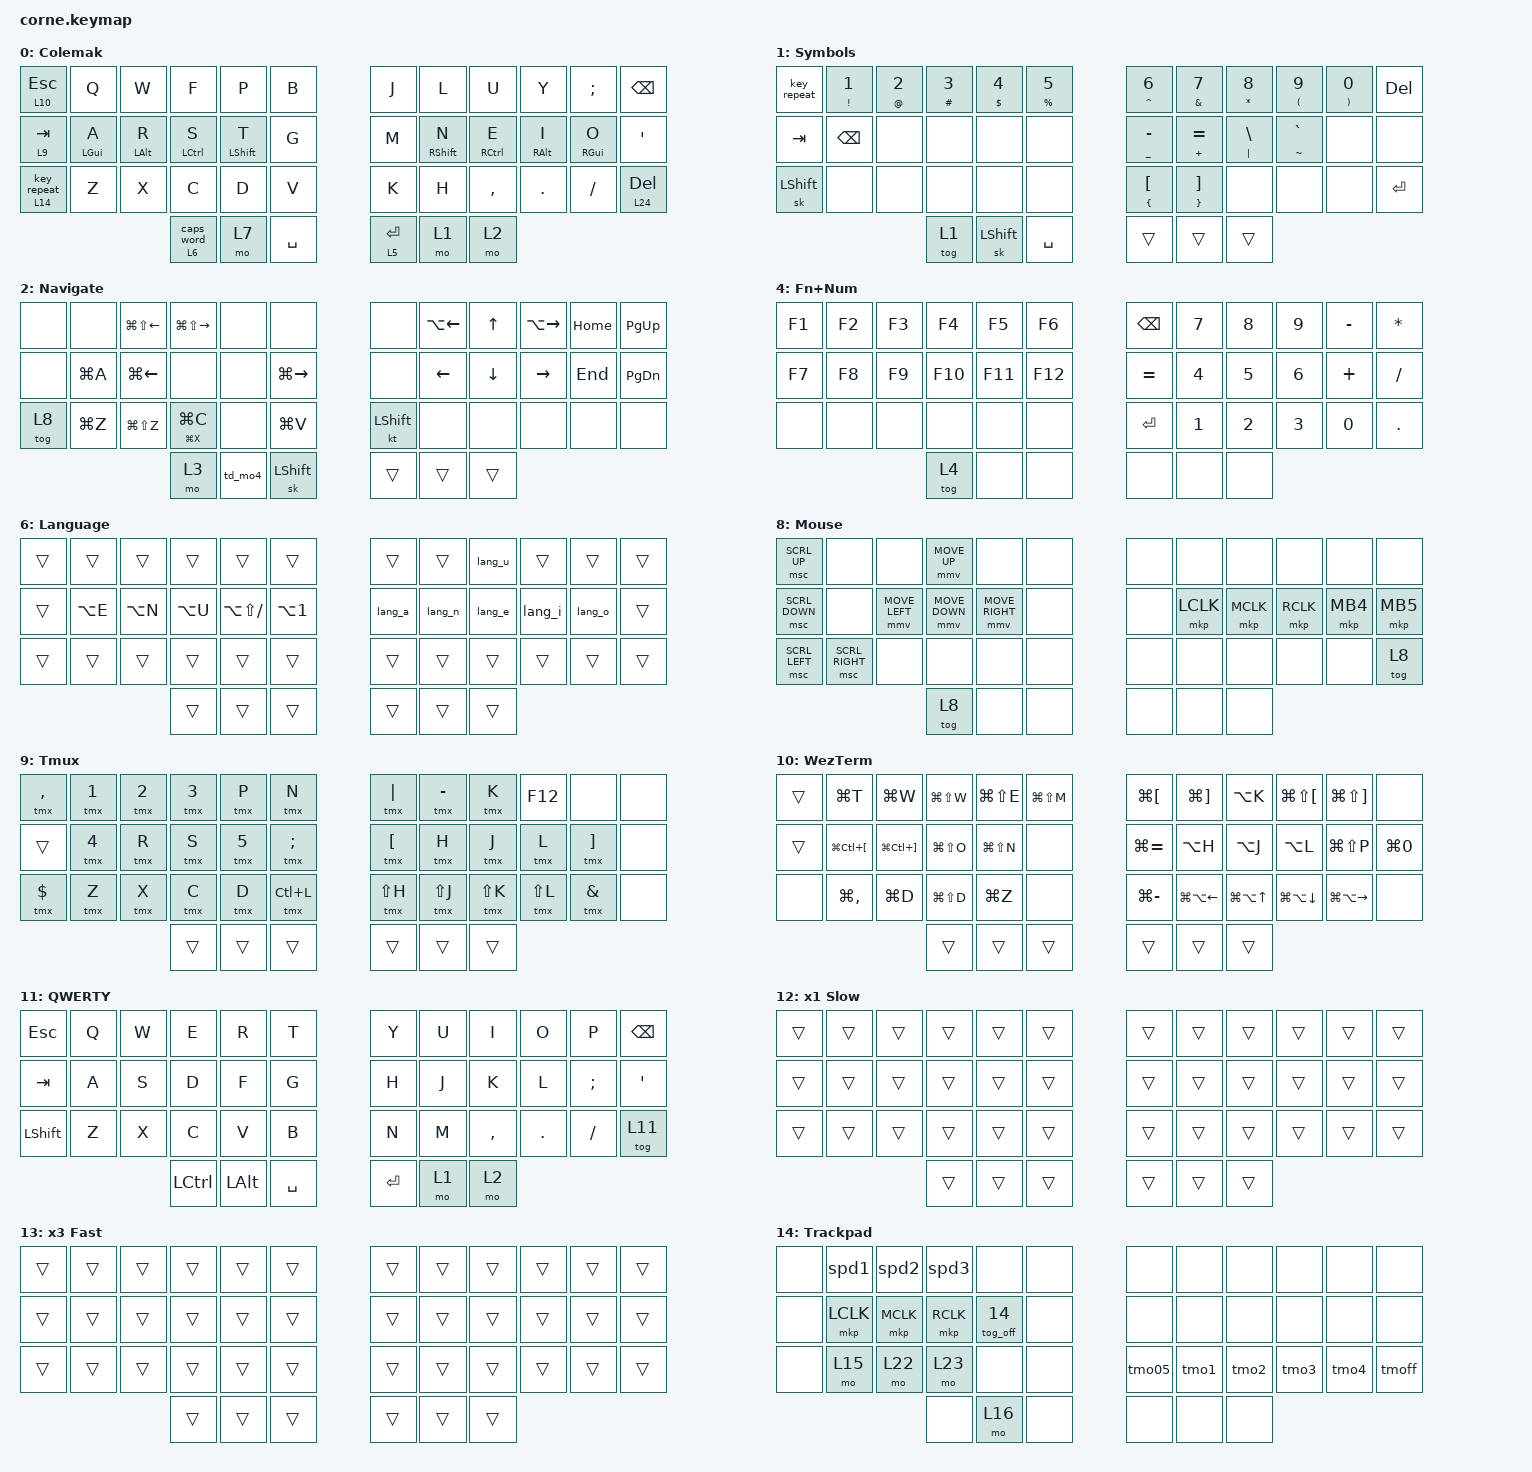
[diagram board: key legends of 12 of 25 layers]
/*
 * Copyright (c) 2020 The ZMK Contributors
 *
 * SPDX-License-Identifier: MIT
 */

#include <behaviors.dtsi>
#include <dt-bindings/zmk/keys.h>
#include <dt-bindings/zmk/bt.h>
#include <dt-bindings/led/led.h>
#include <dt-bindings/zmk/outputs.h>
#include <dt-bindings/zmk/rgb.h>
#include <dt-bindings/zmk/backlight.h>
#define ZMK_POINTING_DEFAULT_MOVE_VAL 2000  // default: 600
/* 320 = 20 * 16: con CONFIG_ZMK_POINTING_SMOOTH_SCROLLING el host divide
 * cada unidad de rueda por el resolution multiplier (16), así que el valor
 * se multiplica para mantener la velocidad efectiva de siempre (20). */
#define ZMK_POINTING_DEFAULT_SCRL_VAL 320   // default: 10
#include <dt-bindings/zmk/pointing.h>

/* nice!view — CS soldado al pin 010 (P0.10), no al default del adapter (P0.06).
 * pro_micro 16 = P0.10 en nice!nano v2.
 * idx 1 = CS del Cirque (P0.09, activo bajo): el keymap es la última palabra
 * del devicetree y pisaría el array del shield cirque_right, así que las dos
 * entradas viven aquí. En la izquierda la segunda es inofensiva (sin reg 1). */
&nice_view_spi {
    cs-gpios = <&pro_micro 16 GPIO_ACTIVE_HIGH>, <&gpio0 9 GPIO_ACTIVE_LOW>;
};

/* P0.09/P0.10 son pines NFC del nRF52840: liberarlos como GPIO para usar
 * P0.10 como CS del nice!view y P0.09 como CS del Cirque. Escribe UICR al
 * primer boot; solo se revierte borrando UICR. */
&uicr {
    nfct-pins-as-gpios;
};

/ {
    /* ------------------------------------------------------------------ */
    /* Combos                                                               */
    /*   J+L (pos 6+7) → ESC  — accesible sin mover manos del home row    */
    /* ------------------------------------------------------------------ */
    combos {
        compatible = "zmk,combos";
        combo_esc {
            timeout-ms = <50>;
            key-positions = <6 7>;
            bindings = <&kp ESC>;
            /* No en QWERTY (L11): ahí pos 6+7 = Y+U y tipear "yu" dispararía ESC */
            /* Todas las capas menos QWERTY (11). Incluye las fantasma
             * 12-16: los combos filtran por la capa MÁS ALTA activa
             * (combo.c usa zmk_keymap_highest_layer_active), así que sin
             * ellas el combo ESC moría con x1/x3 seleccionado o durante la
             * ventana auto-Trackpad. */
            layers = <0 1 2 3 4 5 6 7 8 9 10 12 13 14 15 16 17 18 19 20 21 22 23 24>;
        };
        combo_sys {
            timeout-ms = <50>;
            key-positions = <38 41>;
            bindings = <&mo 3>;
        };
    };

    behaviors {
        /* Home Row Mods — izquierda: hold solo al presionar mano derecha --- */
        hml: homerow_mods_left {
            compatible = "zmk,behavior-hold-tap";
            #binding-cells = <2>;
            tapping-term-ms = <280>;
            quick-tap-ms = <175>;
            require-prior-idle-ms = <200>;
            flavor = "balanced";
            hold-trigger-key-positions = <6 7 8 9 10 11 18 19 20 21 22 23 30 31 32 33 34 35 39 40 41>;
            hold-trigger-on-release;
            bindings = <&kp>, <&kp>;
        };

        /* Left outer thumb: tap→CapsWord / hold→Lang (L6) -------------------- */
        lang_cw: lang_caps_word {
            compatible = "zmk,behavior-hold-tap";
            #binding-cells = <2>;
            tapping-term-ms = <200>;
            quick-tap-ms = <0>;
            flavor = "tap-preferred";
            bindings = <&mo>, <&caps_word>;
        };

        /* REPT-pos (meñique izq inferior): tap→key_repeat / hold→Trackpad (L14) */
        tp_rept: trackpad_or_repeat {
            compatible = "zmk,behavior-hold-tap";
            #binding-cells = <2>;
            tapping-term-ms = <200>;
            quick-tap-ms = <0>;
            flavor = "tap-preferred";
            bindings = <&mo>, <&key_repeat>;
        };

        /* DEL-pos (meñique der inferior): tap→DEL / hold→Nvim (L24) — espejo
         * del tp_rept izquierdo. */
        nv_del: nvim_or_del {
            compatible = "zmk,behavior-hold-tap";
            #binding-cells = <2>;
            tapping-term-ms = <200>;
            quick-tap-ms = <0>;
            flavor = "tap-preferred";
            bindings = <&mo>, <&kp>;
        };

        /* Toggles explícitos para el selector de velocidad del trackpad ---- */
        tog_on: toggle_layer_on {
            compatible = "zmk,behavior-toggle-layer";
            #binding-cells = <1>;
            toggle-mode = "on";
        };
        tog_off: toggle_layer_off {
            compatible = "zmk,behavior-toggle-layer";
            #binding-cells = <1>;
            toggle-mode = "off";
        };
        /* Selector radio-button x1/x2/x3: capas fantasma 12 (slow) y 13 (fast),
         * transparentes al tipeo; solo conmutan el escalador del trackpad
         * (overrides por capa en cirque_left.overlay). x2 = ninguna activa. */
        spd1: speed_slow_select {
            compatible = "zmk,behavior-macro";
            #binding-cells = <0>;
            bindings = <&tog_off 13>, <&tog_on 12>;
        };
        spd2: speed_normal_select {
            compatible = "zmk,behavior-macro";
            #binding-cells = <0>;
            bindings = <&tog_off 12>, <&tog_off 13>;
        };
        spd3: speed_fast_select {
            compatible = "zmk,behavior-macro";
            #binding-cells = <0>;
            bindings = <&tog_off 12>, <&tog_on 13>;
        };

        /* Selector radio-button del timeout del auto-layer Trackpad: capas
         * fantasma 17-21 (overrides en cirque_left.overlay). 2s = default,
         * ninguna activa. Mientras una esté activa la pantalla muestra su
         * nombre como capa superior (mismo tradeoff que x1/x3). */
        tmo05: tmo_half_select {
            compatible = "zmk,behavior-macro";
            #binding-cells = <0>;
            bindings = <&tog_off 18>, <&tog_off 19>, <&tog_off 20>, <&tog_off 21>, <&tog_on 17>;
        };
        tmo1: tmo_1s_select {
            compatible = "zmk,behavior-macro";
            #binding-cells = <0>;
            bindings = <&tog_off 17>, <&tog_off 19>, <&tog_off 20>, <&tog_off 21>, <&tog_on 18>;
        };
        tmo2: tmo_2s_default_select {
            compatible = "zmk,behavior-macro";
            #binding-cells = <0>;
            bindings = <&tog_off 17>, <&tog_off 18>, <&tog_off 19>, <&tog_off 20>, <&tog_off 21>;
        };
        tmo3: tmo_3s_select {
            compatible = "zmk,behavior-macro";
            #binding-cells = <0>;
            bindings = <&tog_off 17>, <&tog_off 18>, <&tog_off 20>, <&tog_off 21>, <&tog_on 19>;
        };
        tmo4: tmo_4s_select {
            compatible = "zmk,behavior-macro";
            #binding-cells = <0>;
            bindings = <&tog_off 17>, <&tog_off 18>, <&tog_off 19>, <&tog_off 21>, <&tog_on 20>;
        };
        tmoff: tmo_no_auto_select {
            compatible = "zmk,behavior-macro";
            #binding-cells = <0>;
            bindings = <&tog_off 17>, <&tog_off 18>, <&tog_off 19>, <&tog_off 20>, <&tog_on 21>;
        };

        /* Macros capa Nvim (L24): cada una tipea la secuencia <leader>…
         * (leader = SPACE). Solo tienen sentido en modo normal de nvim;
         * en insert tipearían la secuencia literal. FMT envía F mayúscula
         * (<leader>F): la f minúscula es prefijo del grupo find en nvim
         * y dispararía con lag de timeoutlen. */
        nv_sm:  nv_smart_find  { compatible = "zmk,behavior-macro"; #binding-cells = <0>; bindings = <&kp SPACE>, <&kp SPACE>; };
        nv_ff:  nv_find_files  { compatible = "zmk,behavior-macro"; #binding-cells = <0>; bindings = <&kp SPACE>, <&kp F>, <&kp F>; };
        nv_fg:  nv_live_grep   { compatible = "zmk,behavior-macro"; #binding-cells = <0>; bindings = <&kp SPACE>, <&kp F>, <&kp G>; };
        nv_sw:  nv_grep_word   { compatible = "zmk,behavior-macro"; #binding-cells = <0>; bindings = <&kp SPACE>, <&kp S>, <&kp W>; };
        nv_bu:  nv_buffers     { compatible = "zmk,behavior-macro"; #binding-cells = <0>; bindings = <&kp SPACE>, <&kp COMMA>; };
        nv_fr:  nv_recent      { compatible = "zmk,behavior-macro"; #binding-cells = <0>; bindings = <&kp SPACE>, <&kp F>, <&kp R>; };
        nv_h1:  nv_harpoon_1   { compatible = "zmk,behavior-macro"; #binding-cells = <0>; bindings = <&kp SPACE>, <&kp N1>; };
        nv_h2:  nv_harpoon_2   { compatible = "zmk,behavior-macro"; #binding-cells = <0>; bindings = <&kp SPACE>, <&kp N2>; };
        nv_h3:  nv_harpoon_3   { compatible = "zmk,behavior-macro"; #binding-cells = <0>; bindings = <&kp SPACE>, <&kp N3>; };
        nv_h4:  nv_harpoon_4   { compatible = "zmk,behavior-macro"; #binding-cells = <0>; bindings = <&kp SPACE>, <&kp N4>; };
        nv_ha:  nv_harpoon_add { compatible = "zmk,behavior-macro"; #binding-cells = <0>; bindings = <&kp SPACE>, <&kp H>, <&kp A>; };
        nv_ex:  nv_explorer    { compatible = "zmk,behavior-macro"; #binding-cells = <0>; bindings = <&kp SPACE>, <&kp E>; };
        nv_w:   nv_save        { compatible = "zmk,behavior-macro"; #binding-cells = <0>; bindings = <&kp SPACE>, <&kp W>; };
        nv_q:   nv_quit        { compatible = "zmk,behavior-macro"; #binding-cells = <0>; bindings = <&kp SPACE>, <&kp Q>; };
        nv_nh:  nv_nohl        { compatible = "zmk,behavior-macro"; #binding-cells = <0>; bindings = <&kp SPACE>, <&kp H>; };
        nv_gg:  nv_lazygit     { compatible = "zmk,behavior-macro"; #binding-cells = <0>; bindings = <&kp SPACE>, <&kp G>, <&kp G>; };
        nv_gs:  nv_git_status  { compatible = "zmk,behavior-macro"; #binding-cells = <0>; bindings = <&kp SPACE>, <&kp G>, <&kp S>; };
        nv_gd:  nv_git_diff    { compatible = "zmk,behavior-macro"; #binding-cells = <0>; bindings = <&kp SPACE>, <&kp G>, <&kp D>; };
        nv_gb:  nv_git_branch  { compatible = "zmk,behavior-macro"; #binding-cells = <0>; bindings = <&kp SPACE>, <&kp G>, <&kp B>; };
        nv_ca:  nv_code_action { compatible = "zmk,behavior-macro"; #binding-cells = <0>; bindings = <&kp SPACE>, <&kp C>, <&kp A>; };
        nv_rn:  nv_rename      { compatible = "zmk,behavior-macro"; #binding-cells = <0>; bindings = <&kp SPACE>, <&kp R>, <&kp N>; };
        nv_fmt: nv_format      { compatible = "zmk,behavior-macro"; #binding-cells = <0>; bindings = <&kp SPACE>, <&kp LS(F)>; };
        nv_ss:  nv_symbols     { compatible = "zmk,behavior-macro"; #binding-cells = <0>; bindings = <&kp SPACE>, <&kp S>, <&kp S>; };
        nv_xx:  nv_trouble     { compatible = "zmk,behavior-macro"; #binding-cells = <0>; bindings = <&kp SPACE>, <&kp X>, <&kp X>; };
        nv_cc:  nv_claude      { compatible = "zmk,behavior-macro"; #binding-cells = <0>; bindings = <&kp SPACE>, <&kp C>, <&kp C>; };
        nv_cy:  nv_claude_yes  { compatible = "zmk,behavior-macro"; #binding-cells = <0>; bindings = <&kp SPACE>, <&kp C>, <&kp Y>; };
        nv_cd:  nv_claude_deny { compatible = "zmk,behavior-macro"; #binding-cells = <0>; bindings = <&kp SPACE>, <&kp C>, <&kp D>; };
        nv_cp:  nv_claude_add  { compatible = "zmk,behavior-macro"; #binding-cells = <0>; bindings = <&kp SPACE>, <&kp C>, <&kp P>; };
        nv_ct:  nv_ctx_board   { compatible = "zmk,behavior-macro"; #binding-cells = <0>; bindings = <&kp SPACE>, <&kp C>, <&kp T>; };
        nv_te:  nv_test_near   { compatible = "zmk,behavior-macro"; #binding-cells = <0>; bindings = <&kp SPACE>, <&kp LS(T)>, <&kp E>; };
        nv_tc:  nv_test_file   { compatible = "zmk,behavior-macro"; #binding-cells = <0>; bindings = <&kp SPACE>, <&kp LS(T)>, <&kp C>; };
        nv_lt:  nv_term_file   { compatible = "zmk,behavior-macro"; #binding-cells = <0>; bindings = <&kp SPACE>, <&kp L>, <&kp T>; };
        nv_bd:  nv_buf_delete  { compatible = "zmk,behavior-macro"; #binding-cells = <0>; bindings = <&kp SPACE>, <&kp B>, <&kp D>; };
        nv_z:   nv_zen         { compatible = "zmk,behavior-macro"; #binding-cells = <0>; bindings = <&kp SPACE>, <&kp Z>; };

        /* Home Row Mods — derecha: hold solo al presionar mano izquierda -- */
        hmr: homerow_mods_right {
            compatible = "zmk,behavior-hold-tap";
            #binding-cells = <2>;
            tapping-term-ms = <280>;
            quick-tap-ms = <175>;
            require-prior-idle-ms = <200>;
            flavor = "balanced";
            hold-trigger-key-positions = <0 1 2 3 4 5 12 13 14 15 16 17 24 25 26 27 28 29 36 37 38>;
            hold-trigger-on-release;
            bindings = <&kp>, <&kp>;
        };

        /* tap = número / hold = símbolo Shift+número ----------------------- */
        num_sym: num_sym {
            compatible = "zmk,behavior-hold-tap";
            #binding-cells = <2>;
            tapping-term-ms = <280>;
            quick-tap-ms = <175>;
            flavor = "tap-preferred";
            bindings = <&kp>, <&kp>;
        };

        /* tap = acción primaria / hold = acción lenta deliberada (redo, cut) */
        slow_ht: slow_hold_tap {
            compatible = "zmk,behavior-hold-tap";
            #binding-cells = <2>;
            tapping-term-ms = <300>;
            quick-tap-ms = <175>;
            flavor = "tap-preferred";
            bindings = <&kp>, <&kp>;
        };

        /* macOS — Screenshots ------------------------------------------- */
        mac_ss_area: mac_screenshot_area {
            compatible = "zmk,behavior-macro";
            #binding-cells = <0>;
            bindings
                = <&macro_press &kp LGUI>
                , <&macro_press &kp LSHFT>
                , <&macro_tap &kp N4>
                , <&macro_release &kp LSHFT>
                , <&macro_release &kp LGUI>
                ;
        };
        /* ⌘+Ctrl+Shift+4 = selección de área → copia al portapapeles (no guarda archivo) */
        mac_ss_clip: mac_screenshot_area_clipboard {
            compatible = "zmk,behavior-macro";
            #binding-cells = <0>;
            bindings
                = <&macro_press &kp LCTRL>
                , <&macro_press &kp LGUI>
                , <&macro_press &kp LSHFT>
                , <&macro_tap &kp N4>
                , <&macro_release &kp LSHFT>
                , <&macro_release &kp LGUI>
                , <&macro_release &kp LCTRL>
                ;
        };

        /* macOS — Escritorios / Mission Control -------------------------- */
        mac_desk_l: mac_desktop_left {
            compatible = "zmk,behavior-macro";
            #binding-cells = <0>;
            bindings
                = <&macro_press &kp LCTRL>
                , <&macro_tap &kp LEFT>
                , <&macro_release &kp LCTRL>
                ;
        };
        mac_desk_r: mac_desktop_right {
            compatible = "zmk,behavior-macro";
            #binding-cells = <0>;
            bindings
                = <&macro_press &kp LCTRL>
                , <&macro_tap &kp RIGHT>
                , <&macro_release &kp LCTRL>
                ;
        };
        mac_mission: mac_mission_control {
            compatible = "zmk,behavior-macro";
            #binding-cells = <0>;
            bindings
                = <&macro_press &kp LCTRL>
                , <&macro_tap &kp UP>
                , <&macro_release &kp LCTRL>
                ;
        };
        mac_expose: mac_app_expose {
            compatible = "zmk,behavior-macro";
            #binding-cells = <0>;
            bindings
                = <&macro_press &kp LCTRL>
                , <&macro_tap &kp DOWN>
                , <&macro_release &kp LCTRL>
                ;
        };

        /* tmux — prefix = Ctrl+A (ver ~/.tmux.conf) --------------------- */
        /* &tmx KEY → Ctrl+A, KEY.  KEY admite modificadores: &tmx LS(H), &tmx PIPE */
        tmx: tmux_prefix_key {
            compatible = "zmk,behavior-macro-one-param";
            #binding-cells = <1>;
            wait-ms = <10>;
            tap-ms = <10>;
            bindings
                = <&macro_tap &kp LC(A)>
                , <&macro_param_1to1>
                , <&macro_tap &kp MACRO_PLACEHOLDER>
                ;
        };
        lang_a: lang_a_acute {
            compatible = "zmk,behavior-macro";
            #binding-cells = <0>;
            bindings = <&kp LA(E)>, <&kp A>;
        };
        lang_e: lang_e_acute {
            compatible = "zmk,behavior-macro";
            #binding-cells = <0>;
            bindings = <&kp LA(E)>, <&kp E>;
        };
        lang_i: lang_i_acute {
            compatible = "zmk,behavior-macro";
            #binding-cells = <0>;
            bindings = <&kp LA(E)>, <&kp I>;
        };
        lang_o: lang_o_acute {
            compatible = "zmk,behavior-macro";
            #binding-cells = <0>;
            bindings = <&kp LA(E)>, <&kp O>;
        };
        lang_u: lang_u_acute {
            compatible = "zmk,behavior-macro";
            #binding-cells = <0>;
            bindings = <&kp LA(E)>, <&kp U>;
        };
        lang_n: lang_n_tilde {
            compatible = "zmk,behavior-macro";
            #binding-cells = <0>;
            bindings = <&kp LA(N)>, <&kp N>;
        };

        /* tap/hold = MO4 momentáneo · doble-tap = TOG4 (bloquea FnNum) ----- */
        td_mo4: tap_dance_mo4 {
            compatible = "zmk,behavior-tap-dance";
            #binding-cells = <0>;
            tapping-term-ms = <200>;
            bindings = <&mo 4>, <&tog 4>;
        };
    };

    keymap {
        compatible = "zmk,keymap";

/* ### Layer 0 — Base (Colemak-DH + HRM)
 * ESC = tap→ESC · hold→L10 (WezTerm)   combo J+L → ESC alternativo
 * Left thumb: CW/L6 (tap CapsWord·hold Lang) · MO7 (hold Apps).
 * Right: inner=tap RET/hold Mac5 · middle=MO1 · outer=MO2.   Combo SPC+MO2 → Sys 3.
 * DEL: meñique der inferior (Mouse toggle movido a L2 pos V).
 * ,----------------------------------.                ,----------------------------------.
 * |ESC/W|  Q  |  W  |  F  |  P  |  B |                |  J  |  L  |  U  |  Y  |  ;  |BSPC|
 * |-----+-----+-----+-----+-----+----|                |-----+-----+-----+-----+-----+----|
 * | TAB |GUI/A|ALT/R|CTL/S|SHF/T|  G |                |  M  |SHF/N|CTL/E|ALT/I|GUI/O| '  |
 * |-----+-----+-----+-----+-----+----|                |-----+-----+-----+-----+-----+----|
 * |REPT |  Z  |  X  |  C  |  D  |  V |                |  K  |  H  |  ,  |  .  |  /  | DEL|
 * `-------------------------------'                    `-------------------------------'
 *         |CW/L6| MO7 |SPACE|                          |RET/5| MO1 | MO2 |
 *         `---------------------'                       `-------------------'
 */
        layer_0 {
            display-name = "Colemak";
            bindings = <
                &lt 10 ESC      &kp Q       &kp W       &kp F        &kp P        &kp B          &kp J    &kp L        &kp U        &kp Y       &kp SEMI    &kp BSPC
                &lt 9 TAB       &hml LGUI A  &hml LALT R  &hml LCTRL S  &hml LSHFT T  &kp G          &kp M    &hmr RSHFT N  &hmr RCTRL E  &hmr RALT I  &hmr RGUI O  &kp SQT
                &tp_rept 14 0   &kp Z       &kp X       &kp C        &kp D        &kp V          &kp K    &kp H        &kp COMMA    &kp DOT     &kp SLASH   &nv_del 24 DEL
                                            &lang_cw 6 0  &mo 7        &kp SPACE                  &lt 5 RET  &mo 1  &mo 2
            >;
        };

/* ### Layer 1 — Sym  (hold MO1)
 * Números row 0: tap=número, hold=símbolo (1/! 2/@ 3/# 4/$ 5/% 6/^ 7/& 8/* 9/( 0/))
 * Home/bot der: tap=base, hold=Shift(base) — patrón igual a fila numérica (280ms)
 * SK(⇧) thumb izq middle: sticky shift para acceder a cualquier símbolo shifted sin hold
 * SK(⇧) thumb izq outer: sticky shift para fila 3 (mismo dedo, acceso rápido)
 * ,------------------------------------.                ,-----------------------------------.
 * |REPT |1/!  |2/@  |3/#  |4/$  |5/%   |                |6/^  |7/&  |8/*  |9/(  |0/)  |DEL |
 * |-----+-----+-----+-----+-----+------|                |-----+-----+-----+-----+-----+----|
 * | TAB |BSPC |  ·  |  ·  |  ·  |  ·   |                | -/_ | =/+ | \/| | `/~ |     |    |
 * |-----+-----+-----+-----+-----+------|                |-----+-----+-----+-----+-----+----|
 * | SK  |     |     |     |     |      |                | [/{ | ]/} |     |     |     |RET |
 * `-------------------------------------'                `----------------------------------'
 *         |TOG1  |SK(⇧)|SPACE|                             |     |     |    |
 *         `-------------------'                            `-------------------'
 */
        layer_1 {
            display-name = "Symbols";
            bindings = <
                &key_repeat &num_sym EXCL N1  &num_sym AT N2   &num_sym HASH N3  &num_sym DLLR N4  &num_sym PRCNT N5    &num_sym CARET N6  &num_sym AMPS N7  &num_sym STAR N8  &num_sym LPAR N9  &num_sym RPAR N0  &kp DEL
                &kp TAB    &kp BSPC  &none    &none    &none     &none      &num_sym UNDER MINUS  &num_sym PLUS EQUAL  &num_sym PIPE BSLH  &num_sym TILDE GRAVE  &none  &none
                &sk LSHFT  &none     &none    &none    &none    &none       &num_sym LBRC LBKT   &num_sym RBRC RBKT   &none               &none               &none  &kp RET
                                      &tog 1   &sk LSHFT  &kp SPACE             &trans    &trans    &trans
            >;
        };

/* ### Layer 2 — Nav  (hold MO2)
 * Edición texto izquierda / flechas + nav + word-jump
 * SK (thumb izq inner) = sticky shift · KT (K-pos der) = toggle shift para 1 mano
 * Mnemonics izq: A=⌘A · Z=⌘Z(undo) · X=⌘⇧Z(redo) · C=CPY/X · V=⌘V
 * ,------------------------------------.                ,--------------------------------------------.
 * |     |     |⌘⇧←  |⌘⇧→  |     |     |                |     |WJ←  |  ↑  |WJ→  |HOME |PGUP |
 * |-----+-----+-----+-----+-----+------|                |-----+-----+-----+-----+-----+-----|
 * |     | ⌘A  | ⌘←  |     |     | ⌘→   |                |     | ←   |  ↓  |  →  |END  |PGDN |
 * |-----+-----+-----+-----+-----+------|                |-----+-----+-----+-----+-----+-----|
 * |MOUSE| ⌘Z  | ⌘⇧Z |CPY/X|     | ⌘V  |                |KT(⇧)|     |     |     |     |     |
 * `-------------------------------------'               `--------------------------------------------'
 *         | MO3 |TD4* |SK(⇧)|                              |     |     |[hld]|
 *         `-------------------'                            `-------------------'
 * CPY/X = tap ⌘C copy / hold ⌘X cut  (300ms)
 * TD4* = hold→MO4 momentáneo · doble-tap→TOG4 (bloquea FnNum)
 */
        layer_2 {
            display-name = "Navigate";
            bindings = <
                &none  &none      &kp LG(LS(LEFT))  &kp LG(LS(RIGHT))  &none  &none    &none      &kp LA(LEFT)  &kp UP    &kp LA(RIGHT)  &kp HOME  &kp PG_UP
                &none  &kp LG(A)  &kp LG(LEFT)       &none              &none  &kp LG(RIGHT)    &none  &kp LEFT  &kp DOWN  &kp RIGHT  &kp END   &kp PG_DN
                &tog 8 &kp LG(Z)  &kp LG(LS(Z))      &slow_ht LG(X) LG(C)  &none  &kp LG(V)    &kt LSHFT  &none  &none  &none  &none  &none
                               &mo 3  &td_mo4  &sk LSHFT                                &trans  &trans  &trans
            >;
        };

/* ### Layer 3 — Sys  (MO2 + MO3 desde L2, o combo SPC+MO2)
 * Bluetooth, RGB, Backlight, Bootloader, Media, Lock
 * ,----------------------------------.                ,----------------------------------.
 * |BTCLR|PRV  |PLAY |NXT  | BLE  |USB |                |BRI- |BRI+ |     |     |BL-TG|RGB-T|
 * |-----+-----+-----+-----+------+---|                |-----+-----+-----+-----+-----+-----|
 * |SOFF | BT0 | BT1 | BT2 |VOL- |VOL+|                |RGB+ |     | BL- | BL+ |RGB- |RGB++|
 * |-----+-----+-----+-----+------+---|                |-----+-----+-----+-----+-----+-----|
 * |QWRT | BT3 | BT4 | BT5 |MUTE |LCK |                |🟢   | 🔴  | 🔵  | 🟡  |SOFF |BOOT |
 * `-------------------------------'                    `-------------------------------'
 *         | GUI |     |SPACE|                              | RET |     |RALT |
 *         `-------------------'                            `-------------------'
 * QWRT = tog 11: entra/sale del layout QWERTY plano (gaming)
 */
        lower_layer {
            display-name = "System";
            bindings = <
                &bt BT_CLR  &kp C_PREV   &kp C_PP     &kp C_NEXT    &out OUT_BLE  &out OUT_USB    &kp C_BRI_DN                        &kp C_BRI_UP                     &none                              &none                            &bl BL_TOG       &rgb_ug RGB_TOG
                &none       &bt BT_SEL 0 &bt BT_SEL 1 &bt BT_SEL 2  &kp C_VOL_DN  &kp C_VOL_UP   &rgb_ug RGB_EFF                     &none                            &bl BL_DEC                         &bl BL_INC                       &rgb_ug RGB_BRD  &rgb_ug RGB_BRI
                &tog 11     &bt BT_SEL 3 &bt BT_SEL 4 &none         &kp C_MUTE    &kp LG(LC(Q))  &rgb_ug RGB_COLOR_HSB(128, 100,100) &rgb_ug RGB_COLOR_HSB(0,100,100) &rgb_ug RGB_COLOR_HSB(240,100,100) &rgb_ug RGB_COLOR_HSB(64,100,50) &soft_off        &bootloader
                                         &kp LGUI     &none          &kp SPACE                     &kp RET  &none   &trans
            >;
        };

/* ### Layer 4 — FnNum  (hold MO2+TD4 / doble-tap TD4 para bloquear)
 * Izq fila 1: F1-F6 · Izq fila 2: F7-F12 · Der: numpad completo
 * TOG-L (thumb outer izq) = salir del modo bloqueado
 * ,------------------------------------.                ,------------------------------------.
 * | F1  | F2  | F3  | F4  | F5  | F6  |                |  ⌫  |  7  |  8  |  9  |  -  |  *  |
 * |-----+-----+-----+-----+-----+-----|                |-----+-----+-----+-----+-----+-----|
 * | F7  | F8  | F9  | F10 | F11 | F12 |                |  =  |  4  |  5  |  6  |  +  |  /  |
 * |-----+-----+-----+-----+-----+-----|                |-----+-----+-----+-----+-----+-----|
 * |  ·  |  ·  |  ·  |  ·  |  ·  |  · |                |  ⏎  |  1  |  2  |  3  |  0  |  .  |
 * `-------------------------------------'               `------------------------------------'
 *         |TOG-L|[hld]|  ·  |                               |  ·  |  ·  |[hld]|
 *         `-------------------'                             `-------------------'
 */
        functions_layer {
            display-name = "Fn+Num";
            bindings = <
                &kp F1  &kp F2  &kp F3  &kp F4   &kp F5   &kp F6    &kp BSPC   &kp N7  &kp N8  &kp N9  &kp MINUS  &kp STAR
                &kp F7  &kp F8  &kp F9  &kp F10  &kp F11  &kp F12   &kp EQUAL  &kp N4  &kp N5  &kp N6  &kp PLUS   &kp SLASH
                &none   &none   &none   &none    &none    &none     &kp RET    &kp N1  &kp N2  &kp N3  &kp N0     &kp DOT
                                &tog 4  &none    &none               &none      &none   &none
            >;
        };

/* ### Layer 5 — Mac  (hold RALT)
 * Izquierda: macOS shortcuts   Derecha: Rectangle win mgmt (fila 1) + browser nav + display (tmux → Layer 9)
 * Rectangle: ⌥⌘← → ↑ ↓ F(max) ⌫(rst) C(ctr)
 * DSK1-5: requiere activar en Ajustes→Teclado→Atajos→Mission Control
 * MW←/→:  requiere activar "Mover ventana al espacio" en los mismos Ajustes
 * ,--------------------------------------------.                ,-------------------------------------------.
 * |DSK1 |DSK2 |DSK3 |DSK4 |DSK5 | HDE  |                |WIN← |WIN→ |WIN↑ |WIN↓ |⌥⌘F  |⌥⌘⌫  |
 * |-----+-----+-----+-----+-----+------|                |-----+-----+-----+-----+-----+-----|
 * | FQ  |SS📋 |SS/4 | UND | RED | MCrl |                | BCK | CTR |TMX.D|TMX.Z| FWD | EML |
 * |-----+-----+-----+-----+-----+------|                |-----+-----+-----+-----+-----+-----|
 * |     |DSK← |DSK→ |EXP  | MW← | MW→  |                | USR |DSP→ |TMX.N|TMX.%|TMX."| PWD |
 * `--------------------------------------------'                `-------------------------------------------'
 *         |     | GUI |SPACE|                              |     |     |[held]|
 *         `-------------------'                            `-------------------'
 */
        macro_layer {
            display-name = "Macros";
            bindings = <
                &kp LC(N1)       &kp LC(N2)   &kp LC(N3)   &kp LC(N4)   &kp LC(N5)       &kp LG(LA(H))    &kp LA(LG(LEFT))  &kp LA(LG(RIGHT))  &kp LA(LG(UP))  &kp LA(LG(DOWN))  &kp LA(LG(F))  &kp LA(LG(BSPC))
                &kp LG(LA(ESC)) &mac_ss_clip  &mac_ss_area &kp LG(Z)   &kp LG(LS(Z))   &mac_mission     &kp LG(LBKT)      &kp LA(LG(C))      &none       &none        &kp LG(RBKT)   &kp LA(LG(LS(E)))
                &none            &mac_desk_l  &mac_desk_r  &mac_expose  &kp LC(LS(LEFT)) &kp LC(LS(RIGHT)) &kp LA(LG(LS(U)))     &kp LA(LG(LS(RIGHT))) &none    &none         &none      &kp LA(LG(LS(P)))
                                              &none        &kp LGUI     &kp SPACE                          &none             &none              &trans
            >;
        };

/* ### Layer 6 — Lang (hold CPSW)
 * Español: dead keys + ¿ + ¡ en el home row izquierdo.
 * Todo lo demás transparente — las teclas normales siguen funcionando.
 * ´ = ⌥E dead acute → suelta CPSW → escribe vocal → á/é/í/ó/ú
 * ~ = ⌥N dead tilde → suelta CPSW → escribe N → ñ
 * ¨ = ⌥U dead umlaut → suelta CPSW → escribe U → ü
 * ,-----------------------------------.                ,----------------------------------.
 * |     |     |     |     |     |     |                |     |     |     |     |     |    |
 * |-----+-----+-----+-----+-----+-----|                |-----+-----+-----+-----+-----+----|
 * |     |  ´  |  ~  |  ¨  |  ¿  |  ¡  |                |     |     |     |     |     |    |
 * |-----+-----+-----+-----+-----+-----|                |-----+-----+-----+-----+-----+----|
 * |     |     |     |     |     |     |                |     |     |     |     |     |    |
 * `------------------------------------'                `-------------------------------'
 *         |[held]|     |     |                              |     |     |     |
 *         `---------------------'                           `-------------------'
 */
        lang_layer {
            display-name = "Language";
            bindings = <
                &trans  &trans      &trans      &trans      &trans              &trans        &trans &trans &lang_u &trans &trans &trans
                &trans  &kp LA(E)   &kp LA(N)   &kp LA(U)   &kp LA(LS(FSLH))  &kp LA(N1)    &lang_a &lang_n &lang_e &lang_i &lang_o &trans
                &trans  &trans      &trans      &trans      &trans              &trans        &trans &trans &trans &trans &trans &trans
                                    &trans      &trans      &trans                            &trans &trans &trans
            >;
        };

/* ### Layer 7 — Apps  (hold CTL/L7 / izq-medio)
 * Activación: hold CTL/L7 (izq-medio) desde cualquier layer — single key
 * Izq top row : WezTerm (Q=new-tab W=close F=split-V P=split-H) — B vacío
 * Izq home row: Zoom (A=mute R=video S=share T=leave) — G vacío
 * Izq bot row : Claude (Z=new) + Slack (X=mentions C=code D=jump)
 * Der top row : Hammerspoon focus-or-launch (J=Wez L=Slk U=Zoom Y=Chrome ;=cycle-win)
 * Der home row: M=HELP, N=CLU (Claude Desktop focus-or-launch)
 * ,------------------------------------.                ,--------------------------------------------.
 * |⌘Q  |WTAB |WCLS |WSPL-V|WSPL-H|    |                | WEZ | SLK | ZOM | CHR |CYCL |  ·  |
 * |-----+-----+-----+------+------+----|                |-----+-----+-----+-----+-----+-----|
 * |⌃TAB|ZMUT |ZVID |ZSHR  |ZLVE  |    |                |HELP | CLU |  ·  |  ·  |  ·  |  ·  |
 * |-----+-----+-----+------+------+----|                |-----+-----+-----+-----+-----+-----|
 * |⌃⇧TB|CLNEW|SMEN |SCOD  |SJMP  |    |                |  ·  |  ·  |  ·  |  ·  |  ·  |  ·  |
 * `------------------------------------'                `--------------------------------------------'
 *         |CW/L6|[held]|     |                              |⌘RET | MO1 | MO2 |
 *         `-------------------'                             `-------------------'
 */
        apps_layer {
            display-name = "Apps";
            bindings = <
                &kp LG(Q)       &kp LG(T)      &kp LG(W)      &kp LG(D)      &kp LG(LS(D))  &none            &kp LA(LG(LS(W))) &kp LA(LG(LS(S))) &kp LA(LG(LS(Z))) &kp LA(LG(LS(C))) &kp LG(GRAVE) &none
                &kp LC(TAB)     &kp LG(LS(A))  &kp LG(LS(V))  &kp LG(LS(S))  &kp LG(LS(H))  &none            &kp LA(LG(LS(H))) &kp LA(LG(LS(N))) &none             &none             &none  &none
                &kp LC(LS(TAB)) &kp LG(N)      &kp LG(LS(M))  &kp LG(LS(C))  &kp LG(K)      &none            &none             &none             &none             &none             &none  &none
                                       &trans          &trans          &trans                           &kp LG(RET) &trans &trans
            >;
        };

/* ### Layer 8 — Mouse  (tog 8 desde meñique der inferior en L0)
 * Toggle: tap para entrar / tap para salir (TOG8 en pulgar izq o meñique der inferior).
 * Izquierda: movimiento ESDF-like + scroll col externa.
 * Derecha: clics home row (N=LCLK E=MCLK I=RCLK).
 * ,------------------------------------.                ,----------------------------------.
 * |SCRL↑|     |     |  M↑ |     |     |                |     |     |     |     |     |     |
 * |-----+-----+-----+-----+-----+-----|                |-----+-----+-----+-----+-----+-----|
 * |SCRL↓|     | M←  | M↓  | M→  |     |                |     |LCLK |MCLK |RCLK | MB4 | MB5 |
 * |-----+-----+-----+-----+-----+-----|                |-----+-----+-----+-----+-----+-----|
 * |SCRL←|SCRL→|     |     |     |     |                |     |     |     |     |     |EXIT |
 * `-------------------------------------'               `----------------------------------'
 *         | EXIT|     |     |                              |     |     |     |
 *         `-------------------'                            `-------------------'
 */
        mouse_layer {
            display-name = "Mouse";
            bindings = <
                &msc SCRL_UP    &none            &none  &mmv MOVE_UP    &none  &none    &none      &none       &none       &none  &none  &none
                &msc SCRL_DOWN  &none            &mmv MOVE_LEFT  &mmv MOVE_DOWN  &mmv MOVE_RIGHT  &none    &none      &mkp LCLK   &mkp MCLK   &mkp RCLK  &mkp MB4  &mkp MB5
                &msc SCRL_LEFT  &msc SCRL_RIGHT  &none  &none           &none  &none    &none      &none       &none       &none  &none  &tog 8
                                &tog 8           &none  &none                            &none  &none  &none
            >;
        };

/* ### Layer 9 — Tmux  (hold TAB en L0)  prefix = Ctrl+A, cada tecla envía prefix + tecla
 * Izquierda: gestión (ventanas, sesiones, panes). Derecha: nav cluster = L2 arrows.
 * Nav panes: h← j↓ l→ en home row der (N E I) + k↑ en U; resize H J K L en fila 3 der.
 * ,------------------------------------.                ,------------------------------------.
 * |  ,  |  1  |  2  |  3  |  p  |  n  |                |  |  |  -  |  k  |NEST |     |     |
 * |renW |     |     |     |prev |next |                |spl-h|spl-v|pane↑|f12  |     |     |
 * |-----+-----+-----+-----+-----+-----|                |-----+-----+-----+-----+-----+-----|
 * |[hld]|  4  |  r  |  s  |  5  |  ;  |                |  [  |  h  |  j  |  l  |  ]  |     |
 * |     |     |reld |tree |     |last |                |copy |pane←|pane↓|pane→|past |     |
 * |-----+-----+-----+-----+-----+-----|                |-----+-----+-----+-----+-----+-----|
 * |  $  |  z  |  x  |  c  |  d  | C-l |                |  H  |  J  |  K  |  L  |  &  |     |
 * |renS |zoom |kill-|new  |det. |last |                |res← |res↓ |res↑ |res→ |kill-|     |
 * |     |     |pane |win  |     |sess |                |     |     |     |     |win  |     |
 * `-------------------------------------'               `------------------------------------'
 */
        tmux_layer {
            display-name = "Tmux";
            bindings = <
                &tmx COMMA &tmx N1   &tmx N2   &tmx N3   &tmx P     &tmx N       &tmx PIPE   &tmx MINUS  &tmx K      &kp F12     &none       &none
                &trans     &tmx N4   &tmx R    &tmx S    &tmx N5    &tmx SEMI    &tmx LBKT   &tmx H      &tmx J      &tmx L      &tmx RBKT   &none
                &tmx DLLR  &tmx Z    &tmx X    &tmx C    &tmx D     &tmx LC(L)   &tmx LS(H)  &tmx LS(J)  &tmx LS(K)  &tmx LS(L)  &tmx AMPS   &none
                                     &trans    &trans    &trans                   &trans      &trans      &trans
            >;
        };

/* ### Layer 10 — WezTerm  (hold ESC en L0)  shortcuts CMD+key / OPT+key
 * Izquierda: gestión (tabs, panes, workspaces). Derecha: nav cluster espeja L9 y L2.
 * Nav panes: ⌥H← ⌥J↓ ⌥L→ en home row der (N E I) + ⌥K↑ en U; resize con ⌘⌥ en fila 3 der.
 * ,-----------------------------------.                ,------------------------------------.
 * |[hld]|NTAB |CTAB |CPANE|TABS |LNCH|                |TAB← |TAB→ |PAN↑ |MOV← |MOV→ |  ·  |
 * |     |⌘T   |⌘W   |⌘⇧W  |⌘⇧E  |⌘⇧M |                |⌘[   |⌘]   |⌥K   |⌘⇧[  |⌘⇧]  |     |
 * |-----+-----+-----+-----+-----+----|                |-----+-----+-----+-----+-----+-----|
 * |     |WS←  |WS→  |WSSL |WSNW |  · |                | F+  |PAN← |PAN↓ |PAN→ |PSEL | F0  |
 * |     |⌘⌃[  |⌘⌃]  |⌘⇧O  |⌘⇧N  |    |                |⌘=   |⌥H   |⌥J   |⌥L   |⌘⇧P  |⌘0   |
 * |-----+-----+-----+-----+-----+----|                |-----+-----+-----+-----+-----+-----|
 * |  ·  |RNM  |SPLH |SPLV |ZOM  |  · |                | F-  |RES← |RES↑ |RES↓ |RES→ |  ·  |
 * |     |⌘,   |⌘D   |⌘⇧D  |⌘Z   |    |                |⌘-   |⌘⌥←  |⌘⌥↑  |⌘⌥↓  |⌘⌥→  |     |
 * `-----------------------------------'                `------------------------------------'
 *         |     |     |     |                              |     |     |     |
 *         `-----+-----+-----'                              `-----+-----+-----'
 */
        wezterm_layer {
            display-name = "WezTerm";
            bindings = <
                &trans  &kp LG(T)          &kp LG(W)          &kp LG(LS(W))     &kp LG(LS(E))     &kp LG(LS(M))    &kp LG(LBKT)      &kp LG(RBKT)      &kp LA(K)           &kp LG(LS(LBKT))    &kp LG(LS(RBKT))    &none
                &trans  &kp LG(LC(LBKT))   &kp LG(LC(RBKT))   &kp LG(LS(O))     &kp LG(LS(N))     &none            &kp LG(EQUAL)     &kp LA(H)         &kp LA(J)           &kp LA(L)           &kp LG(LS(P))       &kp LG(N0)
                &none   &kp LG(COMMA)      &kp LG(D)          &kp LG(LS(D))     &kp LG(Z)         &none            &kp LG(MINUS)     &kp LG(LA(LEFT))  &kp LG(LA(UP))      &kp LG(LA(DOWN))    &kp LG(LA(RIGHT))   &none
                                           &trans             &trans            &trans                              &trans            &trans            &trans
            >;
        };

/* ### Layer 11 — QWERTY  (tog 11 desde Sys, meñique izq inferior — mismo patrón sticky que Mouse)
 * Layout QWERTY plano para juegos o cuando se necesite QWERTY real:
 * SIN home-row mods ni hold-taps — WASD sostenido no dispara modificadores.
 * Thumbs izq: CTRL / ALT / SPACE (gaming). Thumbs der: RET / MO1 / MO2 (números y flechas siguen a mano).
 * EXIT = meñique der inferior (tog 11), igual que Mouse. Sys sigue accesible via combo thumbs 38+41.
 * ,------------------------------------.                ,------------------------------------.
 * | ESC |  Q  |  W  |  E  |  R  |  T  |                |  Y  |  U  |  I  |  O  |  P  | BSPC|
 * |-----+-----+-----+-----+-----+-----|                |-----+-----+-----+-----+-----+-----|
 * | TAB |  A  |  S  |  D  |  F  |  G  |                |  H  |  J  |  K  |  L  |  ;  |  '  |
 * |-----+-----+-----+-----+-----+-----|                |-----+-----+-----+-----+-----+-----|
 * |SHFT |  Z  |  X  |  C  |  V  |  B  |                |  N  |  M  |  ,  |  .  |  /  |EXIT |
 * `-------------------------------------'               `------------------------------------'
 *         |CTRL | ALT |SPACE|                               | RET | MO1 | MO2 |
 *         `-------------------'                             `-------------------'
 */
        qwerty_layer {
            display-name = "QWERTY";
            bindings = <
                &kp ESC    &kp Q  &kp W  &kp E  &kp R  &kp T    &kp Y  &kp U  &kp I      &kp O    &kp P      &kp BSPC
                &kp TAB    &kp A  &kp S  &kp D  &kp F  &kp G    &kp H  &kp J  &kp K      &kp L    &kp SEMI   &kp SQT
                &kp LSHFT  &kp Z  &kp X  &kp C  &kp V  &kp B    &kp N  &kp M  &kp COMMA  &kp DOT  &kp SLASH  &tog 11
                                  &kp LCTRL  &kp LALT  &kp SPACE    &kp RET  &mo 1  &mo 2
            >;
        };

/* ### Layers 12/13 — Speed x1 / x3 (fantasma)
 * 100% transparentes al tipeo: su único efecto es conmutar el escalador del
 * trackpad Cirque (overrides por capa en cirque_left.overlay). Selector en
 * Trackpad (L14, fila superior izquierda Q/W/F): x1 / x2 / x3. Nota: mientras
 * x1 o x3 estén activas, la pantalla muestra su nombre como capa superior. */
        speed_slow_layer {
            display-name = "x1 Slow";
            bindings = <
                &trans  &trans  &trans  &trans  &trans  &trans  &trans  &trans  &trans  &trans  &trans  &trans
                &trans  &trans  &trans  &trans  &trans  &trans  &trans  &trans  &trans  &trans  &trans  &trans
                &trans  &trans  &trans  &trans  &trans  &trans  &trans  &trans  &trans  &trans  &trans  &trans
                &trans  &trans  &trans  &trans  &trans  &trans
            >;
        };

        speed_fast_layer {
            display-name = "x3 Fast";
            bindings = <
                &trans  &trans  &trans  &trans  &trans  &trans  &trans  &trans  &trans  &trans  &trans  &trans
                &trans  &trans  &trans  &trans  &trans  &trans  &trans  &trans  &trans  &trans  &trans  &trans
                &trans  &trans  &trans  &trans  &trans  &trans  &trans  &trans  &trans  &trans  &trans  &trans
                &trans  &trans  &trans  &trans  &trans  &trans
            >;
        };

/* ### Layer 14 — Trackpad  (hold REPT-pos, meñique izq inferior en L0)
 * Panel de control del Cirque, 100% operable con la mano izquierda mientras
 * la derecha desliza sobre el pad:
 * - Fila superior izq (Q/W/F): selector persistente de velocidad x1/x2/x3.
 * - Fila inferior der: selector persistente del timeout del auto-layer
 *   (0.5s/1s/2s/3s/4s/sin auto; 2s = default, capas fantasma 17-21).
 * - Home row izq: clicks directos — LCLK en A, MCLK en R, RCLK en S.
 * - T: EXIT (&tog_off 14) — cierra la capa cuando se activó sola al mover
 *   el pad (auto-layer de 4s, zip_tp_auto_layer en cirque_left.overlay).
 * - Z (anular, junto a REPT): hold SCRL → capa fantasma 15, el pad scrollea
 *   en vez de mover el cursor (override en cirque_left.overlay). X/C = lo
 *   mismo a velocidad lenta (1/4, capa 22) y rápida (1/1, capa 23).
 * - Pulgar izq medio (MO7-pos): hold GEST → capa fantasma 16, deslizar el
 *   pad dispara los atajos de Mission Control (swipe ←/→ = escritorio,
 *   ↑ = Mission Control, ↓ = App Exposé) vía zip_gesture_keybind. Los
 *   atajos equivalentes por tecla no viven acá (duplicarían el gesto).
 * ,------------------------------------.                ,----------------------------------.
 * |     | x1  | x2  | x3  |     |     |                |     |     |     |     |     |     |
 * |-----+-----+-----+-----+-----+-----|                |-----+-----+-----+-----+-----+-----|
 * |     |LCLK |MCLK |RCLK |EXIT |     |                |     |     |     |     |     |     |
 * |-----+-----+-----+-----+-----+-----|                |-----+-----+-----+-----+-----+-----|
 * |[hld]|SCRL |SCR− |SCR+ |     |     |                |t.5  |t1   |t2   |t3   |t4   |tOFF |
 * `-------------------------------------'               `----------------------------------'
 *         |     |GEST |     |                              |     |     |     |
 *         `-------------------'                            `-------------------'
 */
        trackpad_layer {
            display-name = "Trackpad";
            bindings = <
                &none  &spd1   &spd2      &spd3      &none      &none    &none  &none  &none  &none  &none  &none
                &none  &mkp LCLK  &mkp MCLK  &mkp RCLK  &tog_off 14  &none    &none   &none  &none  &none  &none  &none
                &none  &mo 15  &mo 22     &mo 23     &none      &none    &tmo05  &tmo1  &tmo2  &tmo3  &tmo4  &tmoff
                               &none      &mo 16     &none                      &none  &none  &none
            >;
        };

/* ### Layer 15 — Scroll (fantasma): mientras está activa, los deltas del
 * Cirque se mapean a rueda de scroll (override por capa en
 * cirque_left.overlay). Transparente al tipeo, igual que 12/13. */
        tp_scroll_layer {
            display-name = "Scroll";
            bindings = <
                &trans  &trans  &trans  &trans  &trans  &trans  &trans  &trans  &trans  &trans  &trans  &trans
                &trans  &trans  &trans  &trans  &trans  &trans  &trans  &trans  &trans  &trans  &trans  &trans
                &trans  &trans  &trans  &trans  &trans  &trans  &trans  &trans  &trans  &trans  &trans  &trans
                &trans  &trans  &trans  &trans  &trans  &trans
            >;
        };

/* ### Layer 16 — Gesture (fantasma): mientras está activa (hold GEST en
 * Trackpad), deslizar el pad dispara atajos de Mission Control en vez de
 * mover el cursor: swipe → = Ctrl+→ (escritorio der), ← = Ctrl+←,
 * ↑ = Ctrl+↑ (Mission Control), ↓ = Ctrl+↓ (App Exposé). Override
 * zip_gesture_keybind en cirque_left.overlay. Transparente al tipeo. */
        tp_gesture_layer {
            display-name = "Gesture";
            bindings = <
                &trans  &trans  &trans  &trans  &trans  &trans  &trans  &trans  &trans  &trans  &trans  &trans
                &trans  &trans  &trans  &trans  &trans  &trans  &trans  &trans  &trans  &trans  &trans  &trans
                &trans  &trans  &trans  &trans  &trans  &trans  &trans  &trans  &trans  &trans  &trans  &trans
                &trans  &trans  &trans  &trans  &trans  &trans
            >;
        };

/* ### Layers 17-21 — Timeout del auto-layer (fantasma)
 * Radio-button del tiempo de desactivación automática de Trackpad (selector
 * en L14, fila inferior derecha): 0.5s/1s/3s/4s/sin-auto. 2s = default
 * (ninguna activa). Cada capa conmuta un override del listener en
 * cirque_left.overlay con distinto parámetro de zip_tp_auto_layer; "sin
 * auto" usa un chain sin el processor. Transparentes al tipeo. */
        tmo_half_layer {
            display-name = "TA 0.5s";
            bindings = <
                &trans  &trans  &trans  &trans  &trans  &trans  &trans  &trans  &trans  &trans  &trans  &trans
                &trans  &trans  &trans  &trans  &trans  &trans  &trans  &trans  &trans  &trans  &trans  &trans
                &trans  &trans  &trans  &trans  &trans  &trans  &trans  &trans  &trans  &trans  &trans  &trans
                &trans  &trans  &trans  &trans  &trans  &trans
            >;
        };

        tmo_1s_layer {
            display-name = "TA 1s";
            bindings = <
                &trans  &trans  &trans  &trans  &trans  &trans  &trans  &trans  &trans  &trans  &trans  &trans
                &trans  &trans  &trans  &trans  &trans  &trans  &trans  &trans  &trans  &trans  &trans  &trans
                &trans  &trans  &trans  &trans  &trans  &trans  &trans  &trans  &trans  &trans  &trans  &trans
                &trans  &trans  &trans  &trans  &trans  &trans
            >;
        };

        tmo_3s_layer {
            display-name = "TA 3s";
            bindings = <
                &trans  &trans  &trans  &trans  &trans  &trans  &trans  &trans  &trans  &trans  &trans  &trans
                &trans  &trans  &trans  &trans  &trans  &trans  &trans  &trans  &trans  &trans  &trans  &trans
                &trans  &trans  &trans  &trans  &trans  &trans  &trans  &trans  &trans  &trans  &trans  &trans
                &trans  &trans  &trans  &trans  &trans  &trans
            >;
        };

        tmo_4s_layer {
            display-name = "TA 4s";
            bindings = <
                &trans  &trans  &trans  &trans  &trans  &trans  &trans  &trans  &trans  &trans  &trans  &trans
                &trans  &trans  &trans  &trans  &trans  &trans  &trans  &trans  &trans  &trans  &trans  &trans
                &trans  &trans  &trans  &trans  &trans  &trans  &trans  &trans  &trans  &trans  &trans  &trans
                &trans  &trans  &trans  &trans  &trans  &trans
            >;
        };

        tmo_off_layer {
            display-name = "TA off";
            bindings = <
                &trans  &trans  &trans  &trans  &trans  &trans  &trans  &trans  &trans  &trans  &trans  &trans
                &trans  &trans  &trans  &trans  &trans  &trans  &trans  &trans  &trans  &trans  &trans  &trans
                &trans  &trans  &trans  &trans  &trans  &trans  &trans  &trans  &trans  &trans  &trans  &trans
                &trans  &trans  &trans  &trans  &trans  &trans
            >;
        };

/* ### Layers 22/23 — Scroll lento / rápido (fantasma)
 * Variantes del modo scroll con otra velocidad: hold X (SCR− 1/4) o
 * hold C (SCR+ 1/1) en Trackpad, en vez de Z (SCRL normal 1/2).
 * Overrides en cirque_left.overlay. Transparentes al tipeo. */
        tp_scroll_slow_layer {
            display-name = "Scrl -";
            bindings = <
                &trans  &trans  &trans  &trans  &trans  &trans  &trans  &trans  &trans  &trans  &trans  &trans
                &trans  &trans  &trans  &trans  &trans  &trans  &trans  &trans  &trans  &trans  &trans  &trans
                &trans  &trans  &trans  &trans  &trans  &trans  &trans  &trans  &trans  &trans  &trans  &trans
                &trans  &trans  &trans  &trans  &trans  &trans
            >;
        };

        tp_scroll_fast_layer {
            display-name = "Scrl +";
            bindings = <
                &trans  &trans  &trans  &trans  &trans  &trans  &trans  &trans  &trans  &trans  &trans  &trans
                &trans  &trans  &trans  &trans  &trans  &trans  &trans  &trans  &trans  &trans  &trans  &trans
                &trans  &trans  &trans  &trans  &trans  &trans  &trans  &trans  &trans  &trans  &trans  &trans
                &trans  &trans  &trans  &trans  &trans  &trans
            >;
        };

/* ### Layer 24 — Nvim  (hold DEL-pos, meñique der inferior en L0)
 * Keymaps de nvim como teclas físicas (macros que tipean <leader>+secuencia;
 * leader = SPACE). SOLO en modo normal — en insert tipearían la secuencia.
 * Diseño: izquierda = buscar/navegar/git · derecha = actuar (Claude/LSP/
 * tests). Fuente: ~/.config/nvim/CORNE_NVIM_LAYER.md (auditado 2026-11-13).
 * ,------------------------------------.                ,------------------------------------.
 * |     | H1  | H2  | H3  | H4  | H+  |                | cc  | cy  | cd  | cp  | ct  |     |
 * |-----+-----+-----+-----+-----+-----|                |-----+-----+-----+-----+-----+-----|
 * |     | ff  | fg  | sw  |bufs |smart|                | ca  | rn  | FMT | ss  | xx  |     |
 * |-----+-----+-----+-----+-----+-----|                |-----+-----+-----+-----+-----+-----|
 * |     | gg  | gs  | gd  | gb  | fr  |                | Te  | Tc  | lt  | bd  | zen |[hld]|
 * `-------------------------------------'               `------------------------------------'
 *         |  q  |  e  |  w  |                              |C-/  |nohl |     |
 *         `-------------------'                            `-------------------'
 */
        nvim_layer {
            display-name = "Nvim";
            bindings = <
                &none  &nv_h1  &nv_h2  &nv_h3  &nv_h4  &nv_ha    &nv_cc  &nv_cy  &nv_cd   &nv_cp  &nv_ct  &none
                &none  &nv_ff  &nv_fg  &nv_sw  &nv_bu  &nv_sm    &nv_ca  &nv_rn  &nv_fmt  &nv_ss  &nv_xx  &none
                &none  &nv_gg  &nv_gs  &nv_gd  &nv_gb  &nv_fr    &nv_te  &nv_tc  &nv_lt   &nv_bd  &nv_z   &none
                               &nv_q   &nv_ex  &nv_w             &kp LC(FSLH)  &nv_nh  &none
            >;
        };
    };
};


&spi3 {
  compatible = "nordic,nrf-spim";
  status = "okay";

  pinctrl-0 = <&spi3_default>;
  pinctrl-1 = <&spi3_sleep>;
  pinctrl-names = "default", "sleep";

  led_strip: ws2812@0 {
    compatible = "worldsemi,ws2812-spi";

    /* SPI */
    reg = <0>; /* ignored, but necessary for SPI bindings */
    spi-max-frequency = <4000000>;

    /* WS2812 */
    chain-length = <27>; /* number of LEDs */
    spi-one-frame = <0x70>;
    spi-zero-frame = <0x40>;
    color-mapping = <LED_COLOR_ID_GREEN
                          LED_COLOR_ID_RED
                          LED_COLOR_ID_BLUE>;
  };
};

